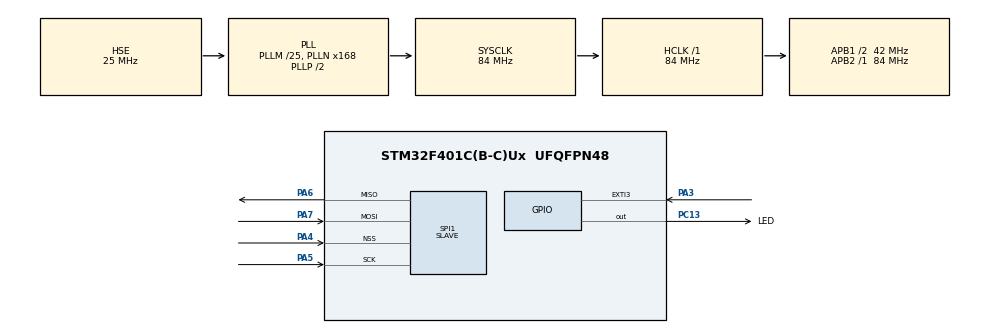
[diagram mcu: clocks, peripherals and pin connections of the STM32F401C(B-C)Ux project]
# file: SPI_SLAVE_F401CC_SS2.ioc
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Dma.Request0=SPI1_RX
Dma.SPI1_RX.0.Direction=DMA_PERIPH_TO_MEMORY
Dma.SPI1_RX.0.FIFOMode=DMA_FIFOMODE_DISABLE
Dma.SPI1_RX.0.Instance=DMA2_Stream0
Dma.SPI1_RX.0.MemDataAlignment=DMA_MDATAALIGN_BYTE
Dma.SPI1_RX.0.MemInc=DMA_MINC_ENABLE
Dma.SPI1_RX.0.Mode=DMA_CIRCULAR
Dma.SPI1_RX.0.PeriphDataAlignment=DMA_PDATAALIGN_BYTE
Dma.SPI1_RX.0.PeriphInc=DMA_PINC_DISABLE
Dma.SPI1_RX.0.Priority=DMA_PRIORITY_VERY_HIGH
Mcu.Family=STM32F4
Mcu.Name=STM32F401C(B-C)Ux
Mcu.Package=UFQFPN48
NVIC.DMA2_Stream0_IRQn=true\:0\:0\:false\:false\:true\:false\:true\:true
NVIC.EXTI3_IRQn=true\:0\:0\:false\:false\:true\:true\:true\:true
NVIC.PriorityGroup=NVIC_PRIORITYGROUP_4
PA13.Mode=Serial_Wire
PA13.Signal=SYS_JTMS-SWDIO
PA14.Mode=Serial_Wire
PA14.Signal=SYS_JTCK-SWCLK
PA3.GPIO_ModeDefaultEXTI=GPIO_MODE_IT_FALLING
PA3.Signal=GPXTI3
PA4.Mode=NSS_Signal_Hard_Input
PA4.Signal=SPI1_NSS
PA5.Mode=Full_Duplex_Slave
PA5.Signal=SPI1_SCK
PA6.Mode=Full_Duplex_Slave
PA6.Signal=SPI1_MISO
PA7.Mode=Full_Duplex_Slave
PA7.Signal=SPI1_MOSI
PC13-ANTI_TAMP.GPIO_Label=LED
PC13-ANTI_TAMP.Signal=GPIO_Output
PH0\ -\ OSC_IN.Mode=HSE-External-Oscillator
PH0\ -\ OSC_IN.Signal=RCC_OSC_IN
PH1\ -\ OSC_OUT.Mode=HSE-External-Oscillator
PH1\ -\ OSC_OUT.Signal=RCC_OSC_OUT
ProjectManager.HeapSize=0x200
ProjectManager.StackSize=0x400
ProjectManager.TargetToolchain=STM32CubeIDE
RCC.48MHZClocksFreq_Value=42000000
RCC.AHBFreq_Value=84000000
RCC.APB1CLKDivider=RCC_HCLK_DIV2
RCC.APB1Freq_Value=42000000
RCC.APB1TimFreq_Value=84000000
RCC.APB2Freq_Value=84000000
RCC.APB2TimFreq_Value=84000000
RCC.CortexFreq_Value=84000000
RCC.HCLKFreq_Value=84000000
RCC.HSE_VALUE=25000000
RCC.HSI_VALUE=16000000
RCC.LSE_VALUE=32768
RCC.PLLM=25
RCC.PLLN=168
RCC.PLLSourceVirtual=RCC_PLLSOURCE_HSE
RCC.SYSCLKFreq_VALUE=84000000
RCC.SYSCLKSource=RCC_SYSCLKSOURCE_PLLCLK
RCC.VCOOutputFreq_Value=168000000
SPI1.Direction=SPI_DIRECTION_2LINES
SPI1.Mode=SPI_MODE_SLAVE
SPI1.VirtualNSS=VM_NSSHARD
SPI1.VirtualType=VM_SLAVE
board=custom

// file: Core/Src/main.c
/* USER CODE BEGIN Header */
/**
  ******************************************************************************
  * @file           : main.c
  * @brief          : Main program body
  ******************************************************************************
  * @attention
  *
  * <h2><center>&copy; Copyright (c) 2021 STMicroelectronics.
  * All rights reserved.</center></h2>
  *
  * This software component is licensed by ST under BSD 3-Clause license,
  * the "License"; You may not use this file except in compliance with the
  * License. You may obtain a copy of the License at:
  *                        opensource.org/licenses/BSD-3-Clause
  *
  ******************************************************************************
  */
/* USER CODE END Header */
#include "main.h"

SPI_HandleTypeDef hspi1;
DMA_HandleTypeDef hdma_spi1_rx;

/* USER CODE BEGIN PV */
uint8_t dataRx[10],dataTx=3;
/* USER CODE END PV */

void SystemClock_Config(void);
static void MX_GPIO_Init(void);
static void MX_DMA_Init(void);
static void MX_SPI1_Init(void);

int main(void)
{

  /* MCU Configuration--------------------------------------------------------*/

  /* Reset of all peripherals, Initializes the Flash interface and the Systick. */
  HAL_Init();

  /* Configure the system clock */
  SystemClock_Config();

  /* Initialize all configured peripherals */
  MX_GPIO_Init();
  MX_DMA_Init();
  MX_SPI1_Init();
  /* USER CODE BEGIN 2 */
  HAL_SPI_Receive_DMA(&hspi1, (uint8_t*)&dataRx, 10);
  /* USER CODE END 2 */

  /* Infinite loop */
  /* USER CODE BEGIN WHILE */
  while (1)
  {
	  if(dataRx[0]==1 && dataRx[1]==2 && dataRx[2]==3 && dataRx[3]==4 && dataRx[4]==5 && dataRx[5]==6 && dataRx[6]==7 && dataRx[7]==8 && dataRx[8]==9 && dataRx[9]==10 )
	        HAL_GPIO_WritePin(LED_GPIO_Port, LED_Pin, 0);
	  	  else HAL_GPIO_WritePin(LED_GPIO_Port, LED_Pin, 1);
    /* USER CODE END WHILE */

  }
}

void SystemClock_Config(void)
{
  RCC_OscInitTypeDef RCC_OscInitStruct = {0};
  RCC_ClkInitTypeDef RCC_ClkInitStruct = {0};

  /** Configure the main internal regulator output voltage
  */
  __HAL_RCC_PWR_CLK_ENABLE();
  __HAL_PWR_VOLTAGESCALING_CONFIG(PWR_REGULATOR_VOLTAGE_SCALE2);
  /** Initializes the RCC Oscillators according to the specified parameters
  * in the RCC_OscInitTypeDef structure.
  */
  RCC_OscInitStruct.OscillatorType = RCC_OSCILLATORTYPE_HSE;
  RCC_OscInitStruct.HSEState = RCC_HSE_ON;
  RCC_OscInitStruct.PLL.PLLState = RCC_PLL_ON;
  RCC_OscInitStruct.PLL.PLLSource = RCC_PLLSOURCE_HSE;
  RCC_OscInitStruct.PLL.PLLM = 25;
  RCC_OscInitStruct.PLL.PLLN = 168;
  RCC_OscInitStruct.PLL.PLLP = RCC_PLLP_DIV2;
  RCC_OscInitStruct.PLL.PLLQ = 4;
  if (HAL_RCC_OscConfig(&RCC_OscInitStruct) != HAL_OK)
  {
    Error_Handler();
  }
  /** Initializes the CPU, AHB and APB buses clocks
  */
  RCC_ClkInitStruct.ClockType = RCC_CLOCKTYPE_HCLK|RCC_CLOCKTYPE_SYSCLK
                              |RCC_CLOCKTYPE_PCLK1|RCC_CLOCKTYPE_PCLK2;
  RCC_ClkInitStruct.SYSCLKSource = RCC_SYSCLKSOURCE_PLLCLK;
  RCC_ClkInitStruct.AHBCLKDivider = RCC_SYSCLK_DIV1;
  RCC_ClkInitStruct.APB1CLKDivider = RCC_HCLK_DIV2;
  RCC_ClkInitStruct.APB2CLKDivider = RCC_HCLK_DIV1;

  if (HAL_RCC_ClockConfig(&RCC_ClkInitStruct, FLASH_LATENCY_2) != HAL_OK)
  {
    Error_Handler();
  }
}

static void MX_SPI1_Init(void)
{

  /* SPI1 parameter configuration*/
  hspi1.Instance = SPI1;
  hspi1.Init.Mode = SPI_MODE_SLAVE;
  hspi1.Init.Direction = SPI_DIRECTION_2LINES;
  hspi1.Init.DataSize = SPI_DATASIZE_8BIT;
  hspi1.Init.CLKPolarity = SPI_POLARITY_LOW;
  hspi1.Init.CLKPhase = SPI_PHASE_1EDGE;
  hspi1.Init.NSS = SPI_NSS_HARD_INPUT;
  hspi1.Init.FirstBit = SPI_FIRSTBIT_MSB;
  hspi1.Init.TIMode = SPI_TIMODE_DISABLE;
  hspi1.Init.CRCCalculation = SPI_CRCCALCULATION_DISABLE;
  hspi1.Init.CRCPolynomial = 10;
  if (HAL_SPI_Init(&hspi1) != HAL_OK)
  {
    Error_Handler();
  }

}

static void MX_DMA_Init(void)
{

  /* DMA controller clock enable */
  __HAL_RCC_DMA2_CLK_ENABLE();

  /* DMA interrupt init */
  /* DMA2_Stream0_IRQn interrupt configuration */
  HAL_NVIC_SetPriority(DMA2_Stream0_IRQn, 0, 0);
  HAL_NVIC_EnableIRQ(DMA2_Stream0_IRQn);

}

static void MX_GPIO_Init(void)
{
  GPIO_InitTypeDef GPIO_InitStruct = {0};

  /* GPIO Ports Clock Enable */
  __HAL_RCC_GPIOC_CLK_ENABLE();
  __HAL_RCC_GPIOH_CLK_ENABLE();
  __HAL_RCC_GPIOA_CLK_ENABLE();

  /*Configure GPIO pin Output Level */
  HAL_GPIO_WritePin(LED_GPIO_Port, LED_Pin, GPIO_PIN_RESET);

  /*Configure GPIO pin : LED_Pin */
  GPIO_InitStruct.Pin = LED_Pin;
  GPIO_InitStruct.Mode = GPIO_MODE_OUTPUT_PP;
  GPIO_InitStruct.Pull = GPIO_NOPULL;
  GPIO_InitStruct.Speed = GPIO_SPEED_FREQ_LOW;
  HAL_GPIO_Init(LED_GPIO_Port, &GPIO_InitStruct);

  /*Configure GPIO pin : PA3 */
  GPIO_InitStruct.Pin = GPIO_PIN_3;
  GPIO_InitStruct.Mode = GPIO_MODE_IT_FALLING;
  GPIO_InitStruct.Pull = GPIO_NOPULL;
  HAL_GPIO_Init(GPIOA, &GPIO_InitStruct);

  /* EXTI interrupt init*/
  HAL_NVIC_SetPriority(EXTI3_IRQn, 0, 0);
  HAL_NVIC_EnableIRQ(EXTI3_IRQn);

}

/* USER CODE BEGIN 4 */
void HAL_GPIO_EXTI_Callback(uint16_t GPIO_Pin){
	HAL_SPI_Transmit(&hspi1, (uint8_t*)&dataTx, 1, 0);
}
/* USER CODE END 4 */

void Error_Handler(void)
{
  __disable_irq();
  while (1)
  {
  }
}

/************************ (C) COPYRIGHT STMicroelectronics *****END OF FILE****/
